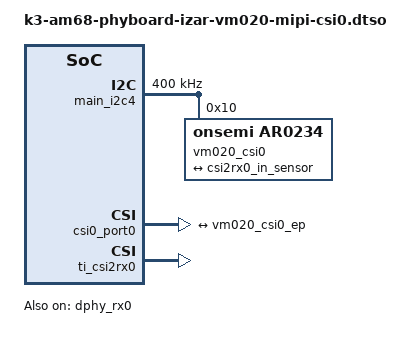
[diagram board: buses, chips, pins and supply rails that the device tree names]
// SPDX-License-Identifier: GPL-2.0
/*
 * Copyright (C) 2023 PHYTEC Messtechnik GmbH
 * Author: Stefan Riedmüller <s.riedmueller@phytec.de>
 */

/dts-v1/;
/plugin/;

#include <dt-bindings/gpio/gpio.h>

&{/} {
	clk_cam_csi0: clk-cam-csi0 {
		compatible = "fixed-clock";
		#clock-cells = <0>;
		clock-frequency = <27000000>;
	};
};

&main_i2c4 {
	clock-frequency = <400000>;
	#address-cells = <1>;
	#size-cells = <0>;
	status = "okay";

	vm020_csi0: vm020-csi0@10 {
		compatible = "onsemi,ar0234";
		reg = <0x10>;

		clock-names = "ext";
		clocks = <&clk_cam_csi0>;

		port {
			vm020_csi0_ep: endpoint {
				remote-endpoint = <&csi2rx0_in_sensor>;
				data-lanes = <1 2 3 4>;
				clock-lanes = <0>;
				clock-noncontinuous = <1>;
				bus-type = <4>; /* MIPI_CSI2_DPHY */
				link-frequencies = /bits/ 64 <450000000>;
			};
		};
	};
};

&csi0_port0 {
	status = "okay";

	csi2rx0_in_sensor: endpoint {
		remote-endpoint = <&vm020_csi0_ep>;
		bus-type = <4>; /* CSI2 DPHY. */
		clock-lanes = <0>;
		data-lanes = <1 2 3 4>;
	};
};

&dphy_rx0 {
	status = "okay";
};

&ti_csi2rx0 {
	status = "okay";
};
